CM_ "IMPORT _honda_common.dbc";
CM_ "IMPORT _bosch_2018.dbc";
CM_ "IMPORT _bosch_radar_acc.dbc";
CM_ "IMPORT _lkas_hud_5byte.dbc";
CM_ "IMPORT _steering_sensors_a.dbc";
CM_ "IMPORT _gearbox_common.dbc";

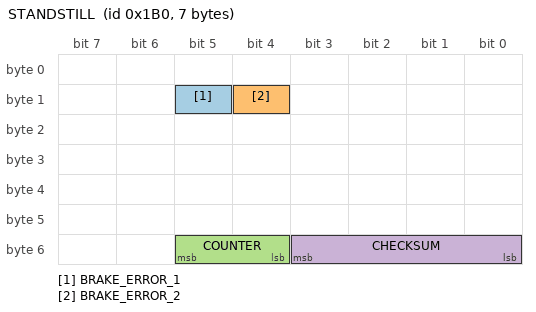
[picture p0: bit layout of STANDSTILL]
BO_ 432 STANDSTILL: 7 VSA
 SG_ BRAKE_ERROR_1 : 13|1@0+ (1,0) [0|1] "" EON
 SG_ BRAKE_ERROR_2 : 12|1@0+ (1,0) [0|1] "" EON
 SG_ COUNTER : 53|2@0+ (1,0) [0|3] "" EON
 SG_ CHECKSUM : 51|4@0+ (1,0) [0|15] "" EON

CM_ BO_ 432 "Slightly conflicting definition with common Bosch standstill message, this one could be broken";
